# Sonata System register map
Vendor: lowRISC; File version: 0.1
Single-core 3-stage pipeline RISC-V processor, 128 KiB on-chip SRAM. 1 x UART, 1 x SPI controller, 1 x PWM channels
CPU: Ibex r0p1, little endian, no MPU, no FPU, VTOR, 2 interrupt priority bits, 1 interrupts
Registers are 32-bit, read-write, no defined reset value unless marked. A register's access mark holds for its fields unless they carry their own. Offsets are from the block's base; lines under a group give offsets from that group; [hi:lo] are bit positions; {n}, {i} and the like mark numbered series; 'fields as' and 'values as' point back to an identical list; <NAME> marks a mode.

## Memory map
0x80000000 GPIO0 size 0x1000 — Gpio port a
0x80000040 GPIO_RPI size 0x1000
0x80000080 GPIO_ARDUINO size 0x1000
0x800000C0 GPIO_PMOD0 size 0x1000
0x80000100 GPIO_PMOD1 size 0x1000
0x80000140 GPIO_PMODC size 0x1000
0x80001000 PWM0 size 0x8 — Simple PWM0
0x80001008 PWM1 size 0x8
0x80001010 PWM2 size 0x8
0x80001018 PWM3 size 0x8
0x80001020 PWM4 size 0x8
0x80001028 PWM5 size 0x8
0x80001030 PWM_LCD size 0x8
0x80040000 TIMER0 size 0x1000 — Controls timer
0x80100000 UART0 size 0x1000 — Full duplex serial communication interface, supports bit rates of up to 1 Mbit/s
0x80100020 UART1 size 0x1000 — Full duplex serial communication interface, supports bit rates of up to 1 Mbit/s
0x80200000 I2C0 size 0x1000 — I2C interface for host and device mode, supporting up to 1 Mbaud data rates
0x80201000 I2C1 size 0x1000
0x80300000 SPI_LCD size 0x1000
0x80301000 SPI_ETHERNET size 0x1000
0x80302000 SPI0 size 0x1000
0x80303000 SPI1 size 0x1000
0x80304000 SPI2 size 0x1000
0x80400000 USBDEV size 0x1000 — USB 2.0 Full Speed device interface (12 Mbit/s)

## Interrupts
1 Transmit watermark (UART0)
2 Receive watermark (UART0)
3 Transmit empty (UART0)
4 Receive overflow (UART0)
5 Receive frame error (UART0)
6 Receive break error (UART0)
7 Receive timeout (UART0)
8 Receive parity error (UART0)
9 Transmit watermark (UART1)
10 Receive watermark (UART1)
11 Transmit empty (UART1)
12 Receive overflow (UART1)
13 Receive frame error (UART1)
14 Receive break error (UART1)
15 Receive timeout (UART1)
16 Receive parity error (UART1)
17 Format FIFO threshold (I2C0)
18 Receive FIFO threshold (I2C0)
19 Acquire FIFO threshold (I2C0)
20 Receive FIFO overflow (I2C0)
21 Received NACK (I2C0)
22 SCL interference (I2C0)
23 SDA interference (I2C0)
24 Stretch timeout (I2C0)
25 SDA unstable (I2C0)
26 Command complete (I2C0)
27 Transmit stretch (I2C0)
28 Transmit threshold (I2C0)
29 Acquire FIFO full (I2C0)
30 Unexpected stop (I2C0)
31 Host timeout (I2C0)
32 Format FIFO threshold (I2C1)
33 Receive FIFO threshold (I2C1)
34 Acquire FIFO threshold (I2C1)
35 Receive FIFO overflow (I2C1)
36 Received NACK (I2C1)
37 SCL interference (I2C1)
38 SDA interference (I2C1)
39 Stretch timeout (I2C1)
40 SDA unstable (I2C1)
41 Command complete (I2C1)
42 Transmit stretch (I2C1)
43 Transmit threshold (I2C1)
44 Acquire FIFO full (I2C1)
45 Unexpected stop (I2C1)
46 Host timeout (I2C1)

## UART0 — Full duplex serial communication interface, supports bit rates of up to 1 Mbit/s
Base 0x80100000
Same registers: UART1 0x80100020
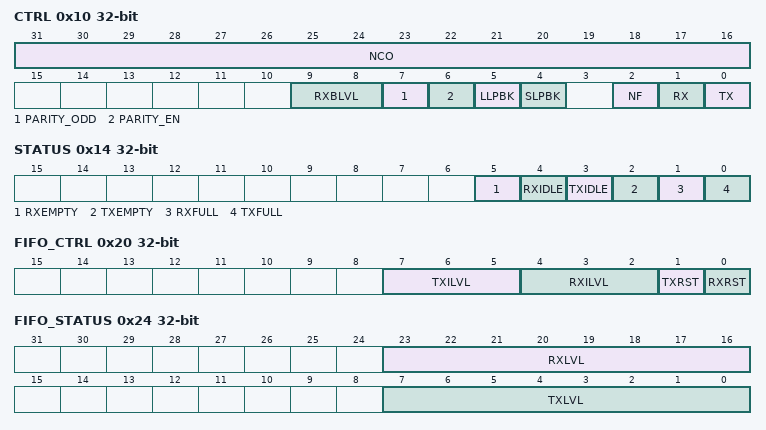
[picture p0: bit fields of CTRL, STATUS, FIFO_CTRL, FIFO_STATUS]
0x10 CTRL — UART control register
  [31:16] NCO — BAUD clock rate control.
  [9:8] RXBLVL — Trigger level for RX break detection. Sets the number of charactertimes the line must be low to detect a break.
  [7] PARITY_ODD — If PARITY_EN is true, this determines the type, 1 for odd parity, 0 for even.
  [6] PARITY_EN — If true, parity is enabled in both RX and TX directions.
  [5] LLPBK — Line loopback enable.If this bit is turned on, incoming bits are forwarded to TX for testing purpose.See Block Diagram. Note that the internal design sees RX value as 1 always if lineloopback is enabled.
  [4] SLPBK — System loopback enable.If this bit is turned on, any outgoing bits to TX are received through RX.See Block Diagram. Note that the TX line goes 1 if System loopback is enabled.
  [2] NF — RX noise filter enable.If the noise filter is enabled, RX line goes through the 3-taprepetition code. It ignores single IP clock period noise.
  [1] RX — RX enable
  [0] TX — TX enable
0x14 STATUS ro — UART live status register
  [5] RXEMPTY — RX FIFO is empty
  [4] RXIDLE — RX is idle
  [3] TXIDLE — TX FIFO is empty and all bits have been transmitted
  [2] TXEMPTY — TX FIFO is empty
  [1] RXFULL — RX buffer is full
  [0] TXFULL — TX buffer is full
0x18 RDATA ro — UART read data
  [7:0] Value
0x1C WDATA wo — UART write data
  [7:0] Value
0x20 FIFO_CTRL — UART FIFO control register
  [7:5] TXILVL — Trigger level for TX interrupts. If the FIFO depth is less than the setting, itraises tx_watermark interrupt.
  [4:2] RXILVL — Trigger level for RX interrupts. If the FIFO depth is greater than or equal tothe setting, it raises rx_watermark interrupt.
  [1] TXRST — TX fifo reset. Write 1 to the register resets TX_FIFO. Read returns 0
  [0] RXRST — RX fifo reset. Write 1 to the register resets RX_FIFO. Read returns 0
0x24 FIFO_STATUS ro — UART FIFO status register
  [23:16] RXLVL — Current fill level of RX fifo
  [7:0] TXLVL — Current fill level of TX fifo
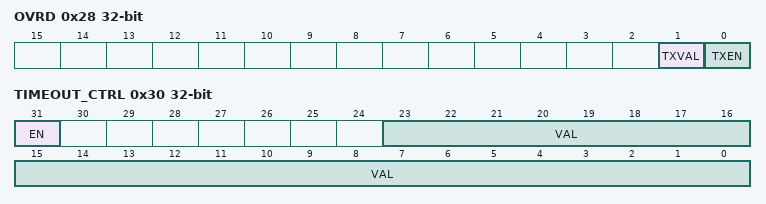
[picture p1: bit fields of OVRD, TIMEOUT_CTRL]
0x28 OVRD — TX pin override control. Gives direct SW control over TX pin state
  [1] TXVAL — Write to set the value of the TX pin
  [0] TXEN — Enable TX pin override control
0x2C VAL ro — UART oversampled values
  [15:0] RX — Last 16 oversampled values of RX. Most recent bit is bit 0, oldest 15.
0x30 TIMEOUT_CTRL — UART RX timeout control
  [31] EN — Enable RX timeout feature
  [23:0] VAL — RX timeout value in UART bit times

## Licence text in the file
Copyright lowRISC contributors. Licensed under the Apache License, Version 2.0, see LICENSE for details. SPDX-License-Identifier: Apache-2.0
